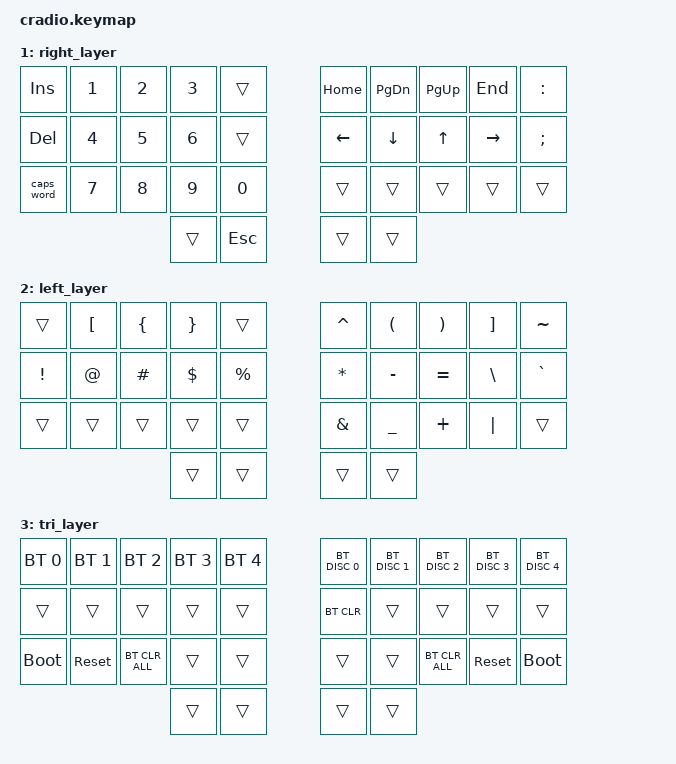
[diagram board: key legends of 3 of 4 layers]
// Copyright (c) 2022 The ZMK Contributors
// SPDX-License-Identifier: MIT

#include <behaviors.dtsi>
#include <dt-bindings/zmk/keys.h>
#include <dt-bindings/zmk/bt.h>

// Home row mods macro
#define HRML(k1,k2,k3,k4) &ht LSHFT k1  &ht LALT k2  &ht LCTRL k3  &ht LGUI k4
#define HRMR(k1,k2,k3,k4) &ht RGUI k1  &ht RCTRL k2  &ht RALT k3  &ht RSHFT k4

/ {
    behaviors {
        ht: hold_tap {
            compatible = "zmk,behavior-hold-tap";
            #binding-cells = <2>;
            flavor = "tap-preferred";
            tapping-term-ms = <220>;
            quick-tap-ms = <150>;
            require-prior-idle-ms = <100>;
            bindings = <&kp>, <&kp>;
        };
    };

    conditional_layers {
        compatible = "zmk,conditional-layers";
        tri_layer {
            if-layers = <1 2>;
            then-layer = <3>;
        };
    };

    keymap {
        compatible = "zmk,keymap";
        default_layer {
            bindings = <
        //╭──────────┬──────────┬──────────┬──────────┬──────────╮   ╭──────────┬──────────┬──────────┬──────────┬──────────╮
        //│  Q       │  W       │  E       │  R       │  T       │   │  Y       │  U       │  I       │  O       │  P       │
            &kp Q      &kp W      &kp E      &kp R      &kp T          &kp Y      &kp U      &kp I      &kp O      &kp P
        //├──────────┼──────────┼──────────┼──────────┼──────────┤   ├──────────┼──────────┼──────────┼──────────┼──────────┤
        //│  A       │  S       │  D       │  F       │  G       │   │  H       │  J       │  K       │  L       │ ' "      │
            HRML(A,        S,         D,         F)     &kp G          &kp H      HRMR(J,        K,         L,        SQT)
        //├──────────┼──────────┼──────────┼──────────┼──────────┤   ├──────────┼──────────┼──────────┼──────────┼──────────┤
        //│  Z       │  X       │  C       │  V       │  B       │   │  N       │  M       │ , <      │ . >      │ / ?      │
            &kp Z      &kp X      &kp C      &kp V      &kp B          &kp N      &kp M      &kp COMMA  &kp DOT    &kp FSLH
        //╰──────────┴──────────┴──────────┼──────────┼──────────┤   ├──────────┼──────────┼──────────┴──────────┴──────────╯
                                           &lt 2 TAB  &kp ENTER       &kp SPACE   &lt 1 BSPC
        //                                 ╰──────────┴──────────╯   ╰──────────┴──────────╯
            >;
        };

        right_layer {
            bindings = <
        //╭──────────┬──────────┬──────────┬──────────┬──────────╮   ╭──────────┬──────────┬──────────┬──────────┬──────────╮
        //│ INSERT   │  1       │  2       │  3       │          │   │ HOME     │ PAGE DN  │ PAGE UP  │ END      │  :       │
            &kp INS    &kp N1     &kp N2     &kp N3     &trans         &kp HOME   &kp PG_DN  &kp PG_UP  &kp END    &kp COLON
        //├──────────┼──────────┼──────────┼──────────┼──────────┤   ├──────────┼──────────┼──────────┼──────────┼──────────┤
        //│ DELETE   │  4       │  5       │  6       │          │   │ LEFT     │ DOWN     │ UP       │ RIGHT    │  ;       │
            &kp DEL    &kp N4     &kp N5     &kp N6     &trans         &kp LEFT   &kp DOWN   &kp UP   &kp RIGHT   &kp SEMI
        //├──────────┼──────────┼──────────┼──────────┼──────────┤   ├──────────┼──────────┼──────────┼──────────┼──────────┤
        //│ CAPS     │  7       │  8       │  9       │  0       │   │          │          │          │          │          │
           &caps_word  &kp N7     &kp N8     &kp N9     &kp N0         &trans     &trans     &trans     &trans     &trans
        //╰──────────┴──────────┴──────────┼──────────┼──────────┤   ├──────────┼──────────┼──────────┴──────────┴──────────╯
                                             &trans     &kp ESC        &trans     &trans
        //                                 ╰──────────┴──────────╯   ╰──────────┴──────────╯
            >;
        };

        left_layer {
            bindings = <
        //╭──────────┬──────────┬──────────┬──────────┬──────────╮   ╭──────────┬──────────┬──────────┬──────────┬──────────╮
        //│          │  [       │  {       │  }       │          │   │  ^       │  (       │  )       │  ]       │  ~       │
            &trans     &kp LBKT   &kp LBRC   &kp RBRC   &trans         &kp CARET  &kp LPAR   &kp RPAR   &kp RBKT   &kp TILDE
        //├──────────┼──────────┼──────────┼──────────┼──────────┤   ├──────────┼──────────┼──────────┼──────────┼──────────┤
        //│  !       │  @       │  #       │  $       │  %       │   │  *       │  -       │  =       │  \       │  `       │
            &kp EXCL   &kp AT     &kp HASH   &kp DLLR   &kp PRCNT      &kp ASTRK  &kp MINUS  &kp EQUAL  &kp BSLH   &kp GRAVE
        //├──────────┼──────────┼──────────┼──────────┼──────────┤   ├──────────┼──────────┼──────────┼──────────┼──────────┤
        //│          │          │          │          │          │   │  &       │  _       │  +       │  │       │          │
            &trans     &trans     &trans     &trans     &trans         &kp AMPS   &kp UNDER  &kp PLUS   &kp PIPE   &trans
        //╰──────────┴──────────┴──────────┼──────────┼──────────┤   ├──────────┼──────────┼──────────┴──────────┴──────────╯
                                             &trans     &trans         &trans     &trans
        //                                 ╰──────────┴──────────╯   ╰──────────┴──────────╯
            >;
        };

        tri_layer {
            bindings = <
        //╭─────────────┬─────────────┬───────────────────────────┬────────────╮   ╭────────────┬────────────┬──────────────┬────────────┬────────────╮
        //│PROFILE0     │PROFILE1     │PROFILE2     │PROFILE3     │PROFILE4    │   │ DISC BT0   │ DISC BT1   │ DISC BT2     │ DISC BT3   │ DISC BT4   │
          &bt BT_SEL 0  &bt BT_SEL 1  &bt BT_SEL 2  &bt BT_SEL 3  &bt BT_SEL 4     &bt BT_DISC 0 &bt BT_DISC 1 &bt BT_DISC 2 &bt BT_DISC 3 &bt BT_DISC 4
        //├─────────────┼─────────────┼─────────────┼─────────────┼────────────┤   ├────────────┼────────────┼──────────────┼────────────┼────────────┤
        //|             │             │             │             │            │   │ CLEAR BT   │            │              │            │            |
            &trans        &trans        &trans        &trans       &trans           &bt BT_CLR    &trans       &trans         &trans       &trans
        //├─────────────┼─────────────┼─────────────┼─────────────┼────────────┤   ├────────────┼────────────┼──────────────┼────────────┼────────────┤
        //│BOOTLOADER   │   RESET     │ CLEAR ALL BT│             │            │   │            │            │CLEAR ALL BT  │  RESET     │BOOTLOADER  │
          &bootloader    &sys_reset    &bt BT_CLR_ALL &trans        &trans           &trans       &trans      &bt BT_CLR_ALL &sys_reset   &bootloader
        //╰─────────────┴─────────────┴─────────────┼─────────────┼────────────┤   ├────────────┼────────────┼──────────────┴────────────┴────────────╯
                                                      &trans        &trans              &trans     &trans
        //                                          ╰─────────────┴────────────╯   ╰────────────┴────────────╯
            >;
        };
    };
};
